# MIMXRT1062 register map
Vendor: nxp.com; File version: 1.0
CPU: CM7 r0p1, little endian, MPU, FPU, VTOR, 4 interrupt priority bits
Registers are 32-bit, read-write, reset 0x0 unless marked. A register's access mark holds for its fields unless they carry their own. Offsets are from the block's base; [hi:lo] are bit positions; {n}, {i} and the like mark numbered series.

## OCOTP
Base 0x401F4000
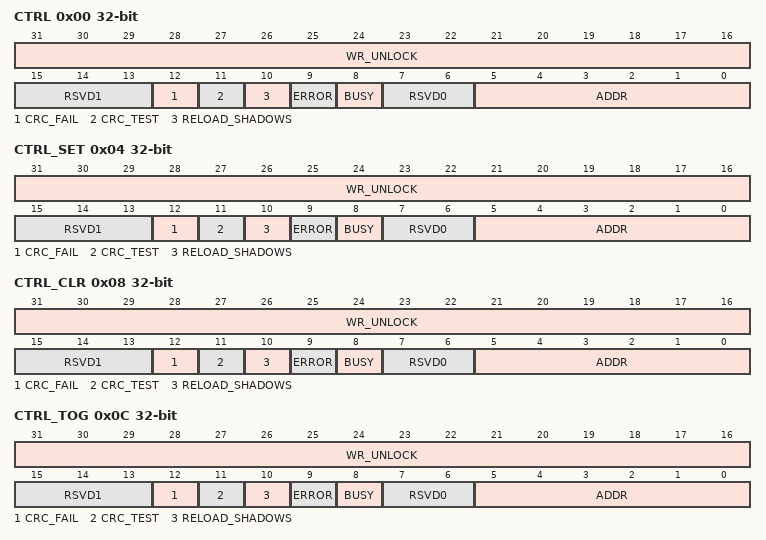
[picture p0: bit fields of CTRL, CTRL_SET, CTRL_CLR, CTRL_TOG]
0x00 CTRL — OTP Controller Control Register
  [31:16] WR_UNLOCK
    0x3E77=KEY (Key needed to unlock HW_OCOTP_DATA register.)
  [15:13] RSVD1 ro
  [12] CRC_FAIL
  [11] CRC_TEST
  [10] RELOAD_SHADOWS
  [9] ERROR
  [8] BUSY ro
  [7:6] RSVD0 ro
  [5:0] ADDR
0x04 CTRL_SET — OTP Controller Control Register
  [31:16] WR_UNLOCK write-1-sets, [15:13] RSVD1 ro write-1-sets, [12] CRC_FAIL write-1-sets, [11] CRC_TEST write-1-sets, [10] RELOAD_SHADOWS write-1-sets, [9] ERROR write-1-sets, [8] BUSY ro write-1-sets, [7:6] RSVD0 ro write-1-sets, [5:0] ADDR write-1-sets
0x08 CTRL_CLR — OTP Controller Control Register
  [31:16] WR_UNLOCK write-1-clears, [15:13] RSVD1 ro write-1-clears, [12] CRC_FAIL write-1-clears, [11] CRC_TEST write-1-clears, [10] RELOAD_SHADOWS write-1-clears, [9] ERROR write-1-clears, [8] BUSY ro write-1-clears, [7:6] RSVD0 ro write-1-clears, [5:0] ADDR write-1-clears
0x0C CTRL_TOG — OTP Controller Control Register
  [31:16] WR_UNLOCK write-1-toggles, [15:13] RSVD1 ro write-1-toggles, [12] CRC_FAIL write-1-toggles, [11] CRC_TEST write-1-toggles, [10] RELOAD_SHADOWS write-1-toggles, [9] ERROR write-1-toggles, [8] BUSY ro write-1-toggles, [7:6] RSVD0 ro write-1-toggles, [5:0] ADDR write-1-toggles
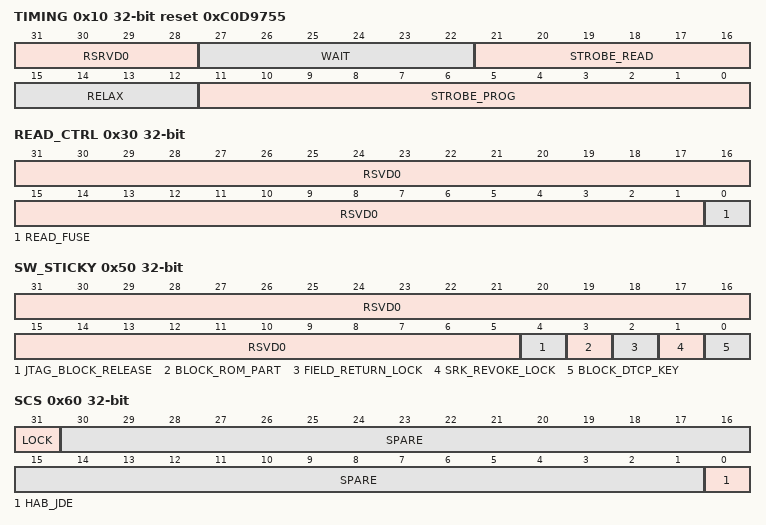
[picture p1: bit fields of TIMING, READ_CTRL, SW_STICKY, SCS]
0x10 TIMING reset 0xC0D9755 — OTP Controller Timing Register
  [31:28] RSRVD0 ro, [27:22] WAIT, [21:16] STROBE_READ, [15:12] RELAX, [11:0] STROBE_PROG
0x20 DATA — OTP Controller Write Data Register
0x30 READ_CTRL — OTP Controller Write Data Register
  [31:1] RSVD0 ro, [0] READ_FUSE
0x40 READ_FUSE_DATA — OTP Controller Read Data Register
0x50 SW_STICKY — Sticky bit Register
  [31:5] RSVD0 ro, [4] JTAG_BLOCK_RELEASE, [3] BLOCK_ROM_PART, [2] FIELD_RETURN_LOCK, [1] SRK_REVOKE_LOCK, [0] BLOCK_DTCP_KEY
0x60 SCS — Software Controllable Signals Register
  [31] LOCK, [30:1] SPARE, [0] HAB_JDE
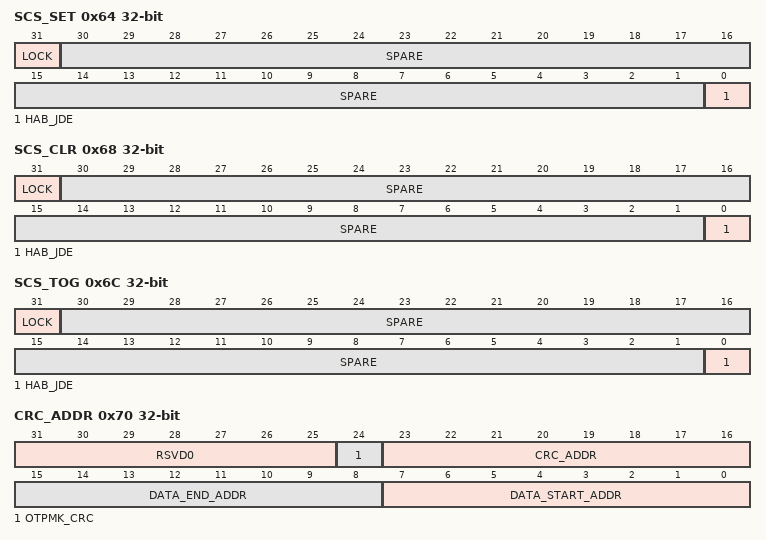
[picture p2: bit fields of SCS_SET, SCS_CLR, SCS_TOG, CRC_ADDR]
0x64 SCS_SET — Software Controllable Signals Register
  [31] LOCK write-1-sets, [30:1] SPARE write-1-sets, [0] HAB_JDE write-1-sets
0x68 SCS_CLR — Software Controllable Signals Register
  [31] LOCK write-1-clears, [30:1] SPARE write-1-clears, [0] HAB_JDE write-1-clears
0x6C SCS_TOG — Software Controllable Signals Register
  [31] LOCK write-1-toggles, [30:1] SPARE write-1-toggles, [0] HAB_JDE write-1-toggles
0x70 CRC_ADDR — OTP Controller CRC test address
  [31:25] RSVD0 ro, [24] OTPMK_CRC, [23:16] CRC_ADDR, [15:8] DATA_END_ADDR, [7:0] DATA_START_ADDR
0x80 CRC_VALUE — OTP Controller CRC Value Register
  [31:0] DATA
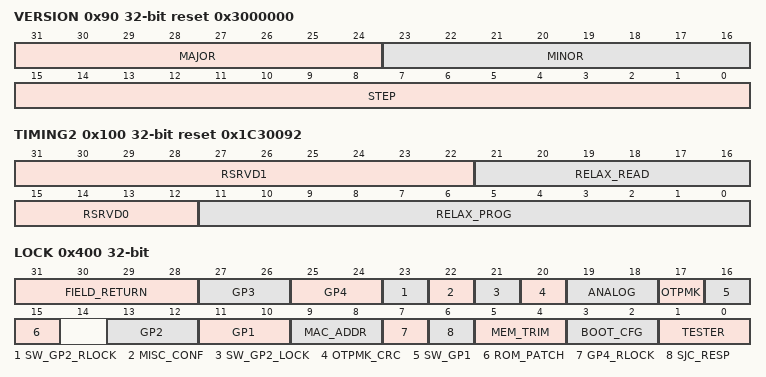
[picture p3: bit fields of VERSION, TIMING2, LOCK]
0x90 VERSION ro reset 0x3000000 — OTP Controller Version Register
  [31:24] MAJOR, [23:16] MINOR, [15:0] STEP
0x100 TIMING2 reset 0x1C30092 — OTP Controller Timing Register
  [31:22] RSRVD1 ro — RSRVD0
  [21:16] RELAX_READ
  [15:12] RSRVD0 ro
  [11:0] RELAX_PROG
0x400 LOCK — Value of OTP Bank0 Word0 (Lock controls)
  [31:28] FIELD_RETURN, [27:26] GP3 ro, [25:24] GP4 ro, [23] SW_GP2_RLOCK ro, [22] MISC_CONF ro, [21] SW_GP2_LOCK ro, [20] OTPMK_CRC ro, [19:18] ANALOG ro, [17] OTPMK ro, [16] SW_GP1 ro, [15] ROM_PATCH ro, [13:12] GP2 ro, [11:10] GP1 ro, [9:8] MAC_ADDR ro, [7] GP4_RLOCK ro, [6] SJC_RESP ro, [5:4] MEM_TRIM ro, [3:2] BOOT_CFG ro, [1:0] TESTER ro
{0x410+0x10*i} CFG{i} (i=0..6) — Value of OTP Bank0 Word{i+1} (Configuration and Manufacturing Info.)
  [31:0] BITS
{0x480+0x10*i} MEM{i} (i=0..4) — Value of OTP Bank1 Word{i} (Memory Related Info.)
  [31:0] BITS
0x4D0 ANA0 — Value of OTP Bank1 Word5 (Memory Related Info.)
  [31:0] BITS
0x4E0 ANA1 — Value of OTP Bank1 Word6 (General Purpose Customer Defined Info.)
  [31:0] BITS
0x4F0 ANA2 — Value of OTP Bank1 Word7 (General Purpose Customer Defined Info.)
  [31:0] BITS
{0x500+0x10*i} OTPMK{i} (i=0..7) — Value of OTP Bank2 Word{i} (OTPMK Key)
  [31:0] BITS
{0x580+0x10*i} SRK{i} (i=0..7) — Shadow Register for OTP Bank3 Word{i} (SRK Hash)
  [31:0] BITS
0x600 SJC_RESP0 — Value of OTP Bank4 Word0 (Secure JTAG Response Field)
  [31:0] BITS
0x610 SJC_RESP1 — Value of OTP Bank4 Word1 (Secure JTAG Response Field)
  [31:0] BITS
0x620 MAC0 — Value of OTP Bank4 Word2 (MAC Address)
  [31:0] BITS
0x630 MAC1 — Value of OTP Bank4 Word3 (MAC Address)
  [31:0] BITS
0x640 MAC2 — Value of OTP Bank4 Word4 (MAC2 Address)
  [31:0] BITS
0x650 OTPMK_CRC32 — Value of OTP Bank4 Word5 (CRC Key)
  [31:0] BITS
0x660 GP1 — Value of OTP Bank4 Word6 (General Purpose Customer Defined Info)
  [31:0] BITS
0x670 GP2 — Value of OTP Bank4 Word7 (General Purpose Customer Defined Info)
  [31:0] BITS
0x680 SW_GP1 — Value of OTP Bank5 Word0 (SW GP1)
  [31:0] BITS
{0x550+0x10*i} SW_GP{i} (i=20..23) — Value of OTP Bank5 Word{i-19} (SW GP2)
  [31:0] BITS
0x6D0 MISC_CONF0 — Value of OTP Bank5 Word5 (Misc Conf)
  [31:0] BITS
0x6E0 MISC_CONF1 — Value of OTP Bank5 Word6 (Misc Conf)
  [31:0] BITS
0x6F0 SRK_REVOKE — Value of OTP Bank5 Word7 (SRK Revoke)
  [31:0] BITS
{0x800+0x10*i} ROM_PATCH{i} (i=0..7) — Value of OTP Bank6 Word{i} (ROM Patch)
  [31:0] BITS
{0x6A0+0x10*i} GP{i} (i=30..33) — Value of OTP Bank7 Word{i-30} (GP3)
  [31:0] BITS
{0x640+0x10*i} GP{i} (i=40..43) — Value of OTP Bank7 Word{i-36} (GP4)
  [31:0] BITS
